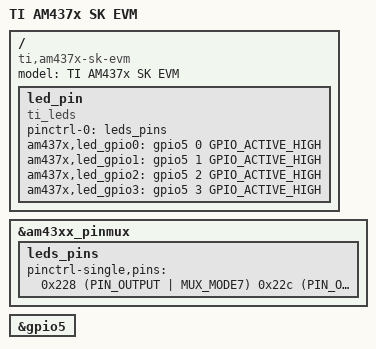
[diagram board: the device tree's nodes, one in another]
/*
 * Copyright (C) 2014 Texas Instruments Incorporated - http://www.ti.com/
 *
 * This program is free software; you can redistribute it and/or modify
 * it under the terms of the GNU General Public License version 2 as
 * published by the Free Software Foundation.
 */

/* AM437x SK EVM */

/dts-v1/;

#include "am4372.dtsi"
#include <dt-bindings/pinctrl/am43xx.h>
#include <dt-bindings/pwm/pwm.h>
#include <dt-bindings/gpio/gpio.h>
#include <dt-bindings/input/input.h>

/ {
	model = "TI AM437x SK EVM";
	compatible = "ti,am437x-sk-evm","ti,am4372","ti,am43";

    led_pin {
        compatible    = "ti_leds";
        pinctrl-names = "default";
        pinctrl-0 = <&leds_pins>;
        am437x,led_gpio0 = <&gpio5 0 GPIO_ACTIVE_HIGH>;
        am437x,led_gpio1 = <&gpio5 1 GPIO_ACTIVE_HIGH>;
        am437x,led_gpio2 = <&gpio5 2 GPIO_ACTIVE_HIGH>;
        am437x,led_gpio3 = <&gpio5 3 GPIO_ACTIVE_HIGH>;
    };
};

&am43xx_pinmux {
	
	leds_pins: leds_pins {
		pinctrl-single,pins = <
			0x228 (PIN_OUTPUT | MUX_MODE7)	/* uart3_rxd.gpio5_2 */
			0x22c (PIN_OUTPUT | MUX_MODE7)	/* uart3_txd.gpio5_3 */
			0x230 (PIN_OUTPUT | MUX_MODE7)	/* uart3_ctsn.gpio5_0 */
			0x234 (PIN_OUTPUT | MUX_MODE7)	/* uart3_rtsn.gpio5_1 */
		>;
	};
};

&gpio5 {
	status = "okay";
};



